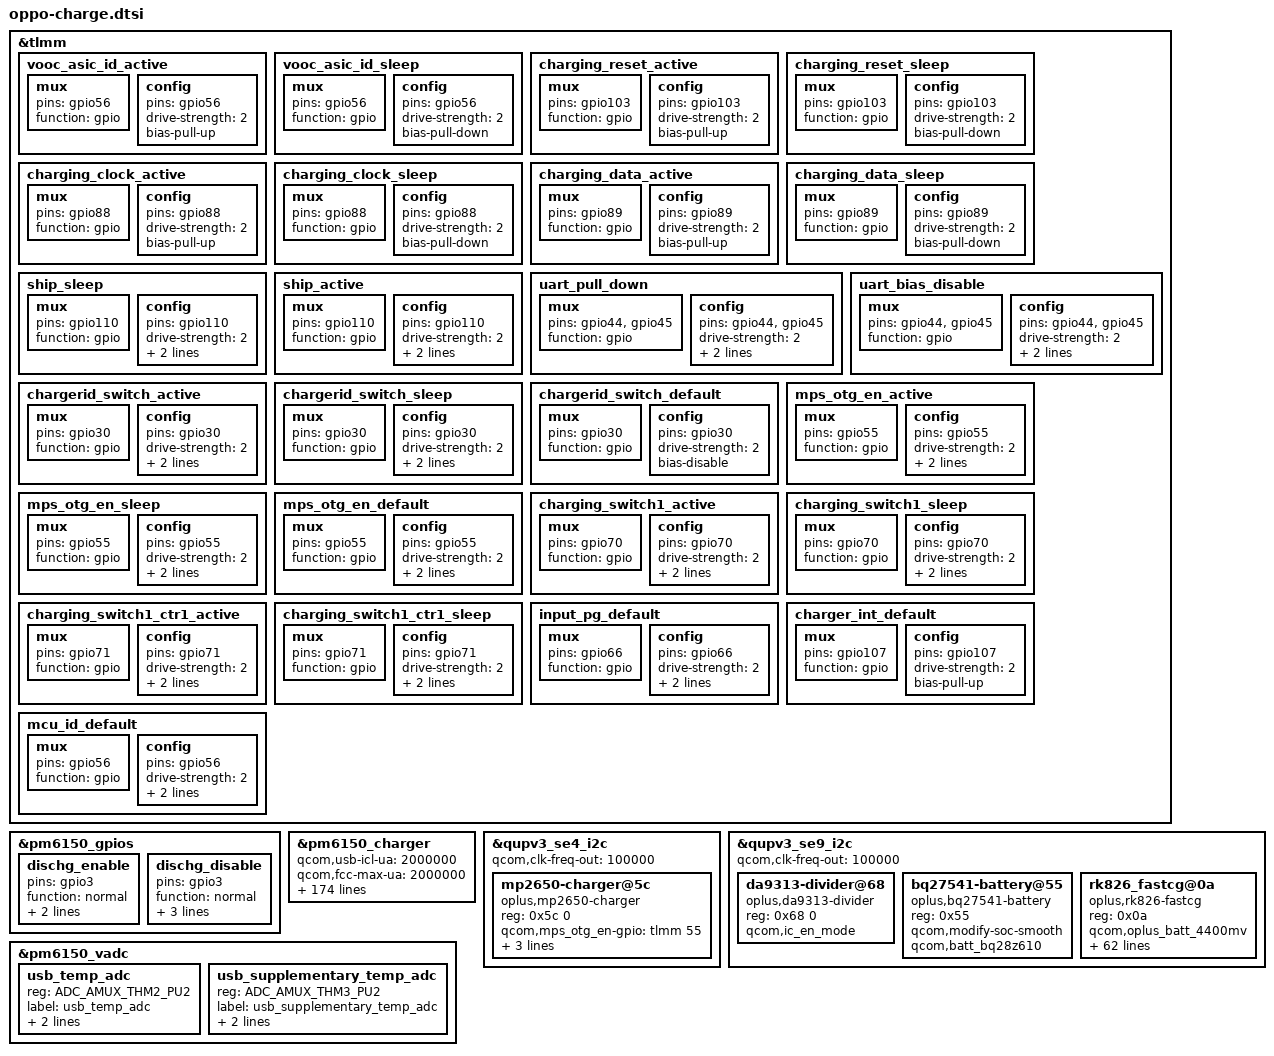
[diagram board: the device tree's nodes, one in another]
/**********************************************************************************
* Copyright (c)  2008-2019  Guangdong OPPO Mobile Comm Corp., Ltd
* VENDOR_EDIT
* Description: OPPO Charge Module Device Tree
* 
* Version: 1.0
* Date: 2019-06-10
* Author: Yichun.Chen
* 
* ------------------------------ Revision History: --------------------------------
* <version>           <date>                <author>                            <desc>
* Revision 1.0       2019-06-10            Yichun.Chen             Created for new architecture
***********************************************************************************/

&tlmm {
	vooc_asic_id_active: vooc_asic_id_active {
		mux {
			pins = "gpio56";
			function = "gpio";
		};

		config {
			pins = "gpio56";
			drive-strength = <2>;
			bias-pull-up;
		};
	};

	vooc_asic_id_sleep: vooc_asic_id_sleep {
		mux {
			pins = "gpio56";
			function = "gpio";
		};

		config {
			pins = "gpio56";
			drive-strength = <2>;
			bias-pull-down;
		};
	};

	charging_reset_active: charging_reset_active {
		mux {
			pins = "gpio103";
			function = "gpio";
		};

		config {
			pins = "gpio103";
			drive-strength = <2>;
			bias-pull-up;
		};
	};

	charging_reset_sleep: charging_reset_sleep {
		mux {
			pins = "gpio103";
			function = "gpio";
		};

		config {
			pins = "gpio103";
			drive-strength = <2>;
			bias-pull-down;
		};
	};

	charging_clock_active: charging_clock_active {
		mux {
			pins = "gpio88";
			function = "gpio";
		};

		config {
			pins = "gpio88";
			drive-strength = <2>;
			bias-pull-up;
		};
	};

	charging_clock_sleep: charging_clock_sleep {
		mux {
			pins = "gpio88";
			function = "gpio";
		};

		config {
			pins = "gpio88";
			drive-strength = <2>;
			bias-pull-down;
		};
	};

	charging_data_active: charging_data_active {
		mux {
			pins = "gpio89";
			function = "gpio";
		};

		config {
			pins = "gpio89";
			drive-strength = <2>;
			bias-pull-up;
		};
	};

	charging_data_sleep: charging_data_sleep {
		mux {
			pins = "gpio89";
			function = "gpio";
		};

		config {
			pins = "gpio89";
			drive-strength = <2>;
			bias-pull-down;
		};
	};

	ship_sleep: ship_sleep {
		mux {
			pins = "gpio110";
			function = "gpio";
		};

		config {
			pins = "gpio110";
			drive-strength = <2>;
			bias-pull-down;
			output-low;
		};
	};

	ship_active: ship_active {
		mux {
			pins = "gpio110";
			function = "gpio";
		};

		config {
			pins = "gpio110";
			drive-strength = <2>;
			bias-pull-up;
			output-high;
		};
	};

	uart_pull_down: uart_pull_down {
		mux {
			pins = "gpio44", "gpio45";
			function = "gpio";
		};

		config {
			pins = "gpio44", "gpio45";
			drive-strength = <2>;
			input-enable;
			bias-pull-down;
		};
	};

	uart_bias_disable: uart_bias_disable {
		mux {
			pins = "gpio44", "gpio45";
			function = "gpio";
		};

		config {
			pins = "gpio44", "gpio45";
			drive-strength = <2>;
			input-enable;
			bias-disable;
		};
	};

	chargerid_switch_active: chargerid_switch_active {
		mux {
			pins = "gpio30";
			function = "gpio";
		};

		config {
			pins = "gpio30";
			drive-strength = <2>;
			bias-pull-up;
			output-high;
		};
	};

	chargerid_switch_sleep: chargerid_switch_sleep {
		mux {
			pins = "gpio30";
			function = "gpio";
		};

		config {
			pins = "gpio30";
			drive-strength = <2>;
			bias-pull-down;
			output-low;
		};
	};

	chargerid_switch_default: chargerid_switch_default {
		mux {
			pins = "gpio30";
			function = "gpio";
		};

		config {
			pins = "gpio30";
			drive-strength = <2>;
			bias-disable;
		};
	};

	mps_otg_en_active: mps_otg_en_active {
		mux {
			pins = "gpio55";
			function = "gpio";
		};

		config {
			pins = "gpio55";
			drive-strength = <2>;
			bias-pull-up;
			output-high;
		};
	};

	mps_otg_en_sleep: mps_otg_en_sleep {
		mux {
			pins = "gpio55";
			function = "gpio";
		};

		config {
			pins = "gpio55";
			drive-strength = <2>;
			bias-pull-down;
			output-low;
		};
	};

	mps_otg_en_default: mps_otg_en_default {
		mux {
			pins = "gpio55";
			function = "gpio";
		};

		config {
			pins = "gpio55";
			drive-strength = <2>;
			bias-pull-down;
			output-low;
		};
	};

	charging_switch1_active: charging_switch1_active {
		mux {
			pins = "gpio70";
			function = "gpio";
		};

		config {
			pins = "gpio70";
			drive-strength = <2>;
			bias-pull-up;
			output-high;
		};
	};

	charging_switch1_sleep: charging_switch1_sleep {
		mux {
			pins = "gpio70";
			function = "gpio";
		};

		config {
			pins = "gpio70";
			drive-strength = <2>;
			bias-pull-down;
			output-low;
		};
	};

	charging_switch1_ctr1_active: charging_switch1_ctr1_active {
		mux {
			pins = "gpio71";
			function = "gpio";
		};

		config {
			pins = "gpio71";
			drive-strength = <2>;
			bias-pull-up;
			output-high;
		};
	};

	charging_switch1_ctr1_sleep: charging_switch1_ctr1_sleep {
		mux {
			pins = "gpio71";
			function = "gpio";
		};

		config {
			pins = "gpio71";
			drive-strength = <2>;
			bias-pull-down;
			output-low;
		};
	};

	input_pg_default: input_pg_default {
		mux {
			pins = "gpio66";
			function = "gpio";
		};

		config {
			pins = "gpio66";
			drive-strength = <2>;
			input-enable;
			bias-pull-up;
		};
	};

	charger_int_default: charger_int_default {
		mux {
			pins = "gpio107";
			function = "gpio";
		};

		config {
			pins = "gpio107";
			drive-strength = <2>;
			bias-pull-up;
		};
	};
/*
	charger_error_default: charger_error_default {
		mux {
			pins = "gpio68";
			function = "gpio";
		};

		config {
			pins = "gpio68";
			drive-strength = <2>;
			input-enable;
			bias-disable;
		};
	};
*/
	mcu_id_default: mcu_id_default {
		mux {
			pins = "gpio56";
			function = "gpio";
		};

		config {
			pins = "gpio56";
			drive-strength = <2>;
			bias-no-pull;
			output-low;
		};
	};

};

&pm6150_gpios {
	dischg_enable: dischg_enable {
		pins = "gpio3";
		function = "normal";
		bias-disable;
		output-high;
	};

	dischg_disable: dischg_disable {
		pins = "gpio3";
		function = "normal";
		bias-disable;
		power-source = <0>;
		output-low;
	};
};

&pm6150_charger {
	qcom,usb-icl-ua = <2000000>;
	qcom,fcc-max-ua = <2000000>;
	//qcom,fv-max-uv = <4373000>;
	qcom,qc3-disable;
	qcom,hvdcp-disable;
	//io-channels = <&pm8150b_vadc ADC_GPIO3>;
	//io-channel-names = "chgID_voltage_adc";
	//qcom,otg-cl-ua = <2000000>;
	qcom,float-option = <1>;

	//for oplus chg framework:
	qcom,input_current_charger_ma = <2000>;
	qcom,pd_input_current_charger_ma = <2000>;
	qcom,qc_input_current_charger_ma = <2000>;

	qcom,input_current_usb_ma = <500>;
	qcom,input_current_cdp_ma = <1500>;
	qcom,input_current_led_ma = <1500>;
	qcom,input_current_led_ma_high = <1200>;
	qcom,input_current_led_ma_warm = <1500>;
	qcom,input_current_led_ma_normal = <2000>;
	qcom,led_warm_bat_decidegc = <350>;
	qcom,led_high_bat_decidegc = <370>;

	qcom,input_current_camera_ma = <1500>;
	qcom,input_current_vooc_led_ma_high = <1200>;
	qcom,input_current_vooc_led_ma_warm = <1800>;
	qcom,input_current_vooc_led_ma_normal = <3600>;
	qcom,input_current_vooc_ma_normal = <3600>;
	qcom,vooc_temp_bat_normal_decidegc = <350>;
	qcom,input_current_vooc_ma_warm = <3200>;
	qcom,vooc_temp_bat_warm_decidegc = <370>;
	qcom,input_current_vooc_ma_high = <2200>;
	qcom,vooc_temp_bat_hot_decidegc = <440>;

	qcom,charger_current_vooc_ma_normal = <1800>;

	qcom,chg_ctrl_by_calling;
	qcom,input_current_calling_ma = <1200>;
	//qcom,input_current_led_ma_overtemp = <900>;
	qcom,overtemp_bat_decidegc = <350>;
	qcom,iterm_disabled = <0>;
	qcom,iterm_ma = <125>;
	qcom,recharge-mv = <100>;
	qcom,batt_capacity_mah = <4500>;/*typical capacity*/
	//qcom,batt_capacity_mah = <3950>; /*rated capacity*/

	qcom,removed_bat_decidegc = <190>;  /*<-19C*/

	qcom,cold_bat_decidegc = <20>;  /*-2C~0C*/
	qcom,temp_cold_vfloat_mv = <3980>;
	qcom,temp_cold_fastchg_current_ma = <300>;

	qcom,little_cold_bat_decidegc = <0>;	/*0C~5C*/
	qcom,temp_little_cold_vfloat_mv = <4435>;
	qcom,temp_little_cold_fastchg_current_ma_high = <1000>;
	qcom,temp_little_cold_fastchg_current_ma_low = <1000>;
	qcom,temp_little_cold_fastchg_current_ma = <1000>;
	qcom,pd_temp_little_cold_fastchg_current_ma_high = <1000>;
	qcom,pd_temp_little_cold_fastchg_current_ma_low = <1000>;
	qcom,qc_temp_little_cold_fastchg_current_ma_high = <1000>;
	qcom,qc_temp_little_cold_fastchg_current_ma_low = <1000>;

	qcom,cool_bat_decidegc = <50>;	/*5C~12C*/
	qcom,temp_cool_vfloat_mv = <4435>;
	qcom,temp_cool_fastchg_current_ma_high = <1100>;
	qcom,temp_cool_fastchg_current_ma_low = <1100>;
	qcom,pd_temp_cool_fastchg_current_ma_high = <2000>;
	qcom,pd_temp_cool_fastchg_current_ma_low = <1410>;
	qcom,qc_temp_cool_fastchg_current_ma_high = <2000>;
	qcom,qc_temp_cool_fastchg_current_ma_low = <1410>;

	qcom,little_cool_bat_decidegc = <120>;	/*12C~16C*/
	qcom,temp_little_cool_vfloat_mv = <4435>;
	qcom,temp_little_cool_fastchg_current_ma = <1100>;
	qcom,pd_temp_little_cool_fastchg_current_ma = <2000>;
	qcom,qc_temp_little_cool_fastchg_current_ma = <2000>;

	qcom,normal_bat_decidegc = <160>;	/*16C~44C*/
	qcom,temp_normal_fastchg_current_ma = <1100>;
	qcom,temp_normal_vfloat_mv = <4435>;
	qcom,pd_temp_normal_fastchg_current_ma = <2000>;
	qcom,qc_temp_normal_fastchg_current_ma = <2000>;

	qcom,warm_bat_decidegc = <450>;	/*45C~53C*/ /*8pin Bat Vooc project need add 3 degree C*/
	qcom,temp_warm_vfloat_mv = <4130>;
	qcom,temp_warm_fastchg_current_ma = <550>;
	qcom,pd_temp_warm_fastchg_current_ma = <550>;
	qcom,qc_temp_warm_fastchg_current_ma = <550>;
	qcom,temp_warm_fastchg_current_ma_led_on = <250>;

	qcom,hot_bat_decidegc = <530>;

	qcom,non_standard_vfloat_mv = <3980>;
	qcom,non_standard_fastchg_current_ma = <512>;

	qcom,short_c_bat_cv_mv = <4330>;
	qcom,short_c_bat_vfloat_mv = <3800>;
	qcom,short_c_bat_fastchg_current_ma = <512>;

	qcom,cold_vfloat_sw_limit = <3930>;
	qcom,little_cold_vfloat_sw_limit = <4385>;
	qcom,cool_vfloat_sw_limit = <4385>;
	qcom,little_cool_vfloat_sw_limit = <4385>;
	qcom,normal_vfloat_sw_limit = <4385>;
	qcom,warm_vfloat_sw_limit = <4080>;
	qcom,non_standard_vfloat_sw_limit = <3930>;
	qcom,short_c_bat_vfloat_sw_limit = <3750>;

	qcom,max_chg_time_sec = <64800>;
	qcom,charger_hv_thr = <9900>;
	qcom,charger_recv_thr = <9500>;
	qcom,charger_lv_thr = <3400>;
	qcom,vbatt_full_thr = <4435>;
	qcom,vbatt_hv_thr = <4600>;
	qcom,vfloat_step_mv = <8>;
	qcom,non_standard_vfloat_over_sw_limit = <3990>;
	qcom,cold_vfloat_over_sw_limit = <3990>;
	qcom,little_cold_vfloat_over_sw_limit = <4445>;
	qcom,cool_vfloat_over_sw_limit = <4445>;
	qcom,little_cool_vfloat_over_sw_limit = <4445>;
	qcom,normal_vfloat_over_sw_limit = <4445>;
	qcom,warm_vfloat_over_sw_limit = <4140>;

	qcom,vbatt_power_off = <3300>;
	qcom,vbatt_soc_1 = <3310>;
	qcom,vooc_project = <3>;
	qcom,vbatt_num = <2>;
	qcom,ffc_support;
	qcom,new_ui_warning_support;
	qcom,dual_ffc;
	recharge_after_full;

	qcom,normal_vterm_hw_inc = <18>;
	qcom,non_normal_vterm_hw_inc = <18>;

	qcom,ff1_normal_fastchg_ma = <550>;
	qcom,ff1_warm_fastchg_ma = <500>;

	qcom,ffc2_normal_fastchg_ma = <350>;/*12C~35c*/
	qcom,ffc2_temp_warm_decidegc = <350>;
	qcom,ffc2_warm_fastchg_ma = <300>;/*35C~40c*/
	qcom,ffc2_temp_high_decidegc = <400>;
	qcom,ffc2_temp_low_decidegc = <120>;

	qcom,ff1_exit_step_ma = <150>;
	qcom,ff1_warm_exit_step_ma = <150>;
	qcom,ffc2_exit_step_ma = <150>;
	qcom,ffc2_warm_exit_step_ma = <150>;


	qcom,ffc_normal_vfloat_sw_limit = <4455>;
	qcom,ffc_temp_normal_vfloat_mv = <4500>;
	qcom,ffc_normal_vfloat_over_sw_limit = <4500>;
	qcom,ffc_warm_vfloat_sw_limit = <4450>;
	qcom,ffc_temp_warm_vfloat_mv = <4500>;
	qcom,ffc_warm_vfloat_over_sw_limit = <4500>;

	qcom,ffc2_normal_vfloat_sw_limit = <4445>;
	qcom,ffc2_temp_normal_vfloat_mv = <4500>;
	qcom,ffc2_normal_vfloat_over_sw_limit = <4500>;
	qcom,ffc2_warm_vfloat_sw_limit = <4440>;
	qcom,ffc2_temp_warm_vfloat_mv = <4500>;
	qcom,ffc2_warm_vfloat_over_sw_limit = <4500>;

	qcom,default_iterm_ma = <125>;
	qcom,default_temp_normal_fastchg_current_ma = <1100>;
	qcom,default_normal_vfloat_sw_limit = <4385>;
	qcom,default_temp_normal_vfloat_mv = <4435>;
	qcom,default_normal_vfloat_over_sw_limit = <4445>;

	qcom,default_temp_little_cool_fastchg_current_ma = <1100>;
	qcom,default_little_cool_vfloat_sw_limit = <4385>;
	qcom,default_temp_little_cool_vfloat_mv = <4435>;
	qcom,default_little_cool_vfloat_over_sw_limit = <4445>;

	///qcom,offset_temp = <30>;
	//for control:
	//qcom,suspend_after_full;
	qcom,check_batt_full_by_sw;
	qcom,external_gauge;
	qcom,chg_ctrl_by_lcd;
	qcom,chg_ctrl_by_vooc;
	qcom,chg_ctrl_by_camera;
	qcom,sw_vfloat_over_protect_enable;

	//for PD9V or QC9V
	qcom,vbatt_pdqc_to_5v_thr = <4100>;

	qcom,vooc_show_ui_soc_decimal;
	qcom,ui_soc_decimal_speedmin = <20>;//2A
	
	/* gpio options */
	qcom,chargerid_switch-gpio = <&tlmm 30 0x00>;
	qcom,ship-gpio = <&tlmm 110 0x00>;
	qcom,dischg-gpio = <&pm6150_gpios 3 0x00>;
	pinctrl-names = "chargerid_switch_active", "chargerid_switch_sleep", "chargerid_switch_default",
			"ship_active", "ship_sleep",
			"dischg_enable", "dischg_disable",
			"charger_int_default",
			"input_pg_default","mcu_id_default";

	pinctrl-0 = <&chargerid_switch_active>;
	pinctrl-1 = <&chargerid_switch_sleep>;
	pinctrl-2 = <&chargerid_switch_default>;
	pinctrl-3 = <&ship_active>;
	pinctrl-4 = <&ship_sleep>;
	pinctrl-5 = <&dischg_enable>;
	pinctrl-6 = <&dischg_disable>;
	pinctrl-7 = <&charger_int_default>;
	pinctrl-8 = <&input_pg_default>;
	pinctrl-9 = <&mcu_id_default>;
};

&qupv3_se4_i2c {
	status = "ok";
	qcom,clk-freq-out = <100000>;

	mp2650-charger@5c {
		status = "ok";
		compatible = "oplus,mp2650-charger";
		reg = <0x5c 0>;

		qcom,mps_otg_en-gpio = <&tlmm 55 0x00>;
		pinctrl-names = "mps_otg_en_active", "mps_otg_en_sleep", "mps_otg_en_default";
		pinctrl-0 = <&mps_otg_en_active>;
		pinctrl-1 = <&mps_otg_en_sleep>;
		pinctrl-2 = <&mps_otg_en_default>;

	};
};


&qupv3_se9_i2c {
	status = "ok";
	qcom,clk-freq-out = <100000>;

	da9313-divider@68 {
		status = "ok";
		compatible = "oplus,da9313-divider";
		reg = <0x68 0>;
		qcom,ic_en_mode;
	};

	bq27541-battery@55 {
		status = "ok";
		compatible = "oplus,bq27541-battery";
		reg = <0x55>;
		qcom,modify-soc-smooth;
		qcom,batt_bq28z610;
	};

	/*oppo_short-ic@58 {
		status = "okay";
		compatible = "oppo,oppo_short-ic";
		reg = <0x58>;
		qcom,modify-soc-smooth;
		qcom,batt_bq28z610;
	};*/

	rk826_fastcg@0a {
		status = "ok";
		compatible = "oplus,rk826-fastcg";
		reg = <0x0a>;
		qcom,oplus_batt_4400mv;
		qcom,support_vooc_by_normal_charger_path;
		//qcom,vooc_fw_update_newmethod;
		qcom,vooc-low-temp = <50>;
		qcom,vooc-high-temp = <430>;
		qcom,vooc-low-soc = <1>;
		qcom,vooc-high-soc = <90>;
		qcom,vooc-little-cool-temp = <160>;
		qcom,vooc-cool-temp = <120>;
		qcom,vooc-little-cool-to-normal-temp = <180>;
		qcom,vooc-normal-to-little-cool-current = <0x05>;//5A
		qcom,vooc-fw-type = <0x05>;//6.5A

		qcom,vooc_multistep_adjust_current_support;
		qcom,vooc_multistep_initial_batt_temp = <310>;
		qcom,vooc_strategy_normal_current = <0x06>;

		qcom,vooc_batt_over_high_temp = <440>;
		qcom,vooc_batt_over_low_temp = <45>;
		qcom,vooc_over_high_or_low_current = <0x0>;

		qcom,vooc_strategy1_batt_high_temp0 = <425>;
		qcom,vooc_strategy1_batt_high_temp1 = <430>;
		qcom,vooc_strategy1_batt_high_temp2 = <435>;
		qcom,vooc_strategy1_batt_low_temp2 = <420>;
		qcom,vooc_strategy1_batt_low_temp1 = <415>;
		qcom,vooc_strategy1_batt_low_temp0 = <400>;

		qcom,vooc_strategy1_high_current0 = <0x04>;//4A
		qcom,vooc_strategy1_high_current1 = <0x03>;//3A
		qcom,vooc_strategy1_high_current2 = <0x02>;//2A
		qcom,vooc_strategy1_low_current2 = <0x03>;//3A
		qcom,vooc_strategy1_low_current1 = <0x04>;//4A
		qcom,vooc_strategy1_low_current0 = <0x04>;//4A

		qcom,vooc_strategy2_batt_up_temp1 = <375>;
		qcom,vooc_strategy2_batt_up_down_temp2 = <380>;
		qcom,vooc_strategy2_batt_up_temp3 = <390>;
		qcom,vooc_strategy2_batt_up_down_temp4 = <400>;
		qcom,vooc_strategy2_batt_up_temp5 = <410>;
		qcom,vooc_strategy2_batt_up_temp6 = <415>;
		qcom,vooc_strategy2_high0_current = <0x05>;
		qcom,vooc_strategy2_high1_current = <0x04>;
		qcom,vooc_strategy2_high2_current = <0x03>;
		qcom,vooc_strategy2_high3_current = <0x02>;
		qcom,vooc_current_lvl = <1000
									1500
									2000
									2500
									3000
									3500
									4000
									4500
									5000
									5500
									6000
									6500
									7000
									7500
									8000
									8500
									9000
									9500
									10000
									10500
									11000
									11500
									12000
									12500>;

		pinctrl-names = "switch1_act_switch2_act", "switch1_sleep_switch2_sleep",
			"switch1_act_switch3_act", "switch1_sleep_switch3_sleep",
			"switch1_act_switch2_sleep", "switch1_sleep_switch2_act",
			"clock_active","clock_sleep",
			"data_active","data_sleep",
			"reset_active","reset_sleep",
			"charging_switch1_ctr1_active","charging_switch1_ctr1_sleep",
			"vooc_asic_id_active","vooc_asic_id_sleep";

		pinctrl-0 = <&charging_switch1_active>;
		pinctrl-1 = <&charging_switch1_sleep >;
		pinctrl-2 = <&charging_switch1_active>;
		pinctrl-3 = <&charging_switch1_sleep >;
		pinctrl-4 = <&charging_switch1_active>;
		pinctrl-5 = <&charging_switch1_sleep>;
		pinctrl-6 = <&charging_clock_active >;
		pinctrl-7 = <&charging_clock_sleep >;
		pinctrl-8 = <&charging_data_active >;
		pinctrl-9 = <&charging_data_sleep >;
		pinctrl-10 = <&charging_reset_active >;
		pinctrl-11 = <&charging_reset_sleep >;
		pinctrl-12 = <&charging_switch1_ctr1_active >;
		pinctrl-13 = <&charging_switch1_ctr1_sleep >;
		pinctrl-14 = <&vooc_asic_id_active>;
		pinctrl-15 = <&vooc_asic_id_sleep>;

		qcom,charging_switch1-gpio = <&tlmm 70 0x00>;
		qcom,charging_switch1_ctr1-gpio = <&tlmm 71 0x00>;
		qcom,charging_reset-gpio = <&tlmm 103 0x00>;
		qcom,charging_clock-gpio = <&tlmm 88 0x00>;
		qcom,charging_data-gpio = <&tlmm 89 0x00>;
		qcom,vooc_asic_id-gpio = <&tlmm 56 0x00>;
	};
};

&pm6150_vadc {
	usb_temp_adc {
		reg = <ADC_AMUX_THM2_PU2>;
		label = "usb_temp_adc";
		qcom,pre-scaling = <1 1>;
		qcom,ratiometric;
	};

	usb_supplementary_temp_adc {
		reg = <ADC_AMUX_THM3_PU2>;
		label = "usb_supplementary_temp_adc";
		qcom,pre-scaling = <1 1>;
		qcom,ratiometric;
	};
};
